# CTRL_MMR0_CFG0 register map
Vendor: Texas Instruments
Peripheral module from a debugger description file (folder J7VCL).
Registers are 32-bit, access per field, reset 0x0 unless marked. A register's access mark holds for its fields unless they carry their own. Offsets are as the file gives them; lines under a group give offsets from that group; [hi:lo] are bit positions; {n}, {i} and the like mark numbered series; 'fields as' and 'values as' point back to an identical list; <NAME> marks a mode.

## CTRL_MMR0_CFG0
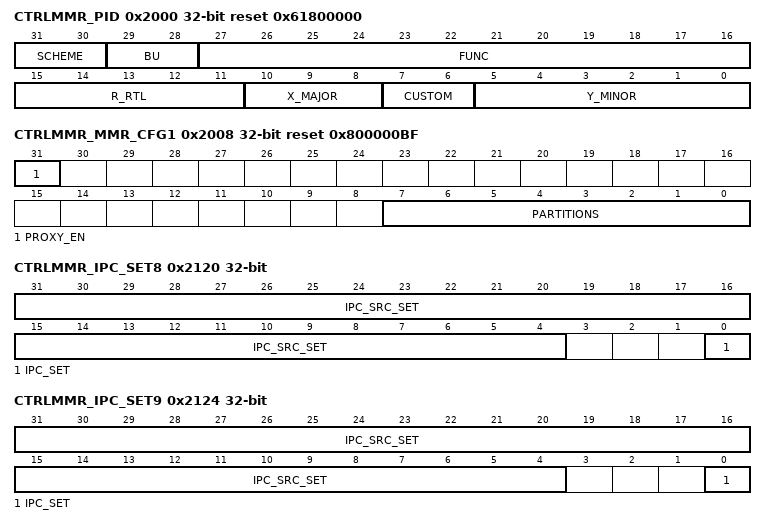
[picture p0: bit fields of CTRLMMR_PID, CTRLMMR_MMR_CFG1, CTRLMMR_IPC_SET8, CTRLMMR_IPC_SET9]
0x2000 CTRLMMR_PID ro reset 0x61800000
  [31:30] SCHEME
  [29:28] BU — Business unit - Processors
  [27:16] FUNC — Module functional identifier - CTRL MMR
  [15:11] R_RTL — RTL revision number
  [10:8] X_MAJOR — Major revision number
  [7:6] CUSTOM — Custom revision number
  [5:0] Y_MINOR — Minor revision number
0x2008 CTRLMMR_MMR_CFG1 ro reset 0x800000BF
  [31] PROXY_EN — Proxy addressing enabled
  [7:0] PARTITIONS — Indicates present partitions
0x2030 CTRLMMR_MAIN_DEVSTAT (reset mask 0xFFFFFF00)
  [7:0] BOOTMODE rw — Specifies the device Primary and Backup boot media.
0x2034 CTRLMMR_MAIN_BOOTCFG ro (reset mask 0xFFFFFF00)
  [7:0] BOOTMODE — Specifies the device Primary and Backup boot media as latched at PORz
0x2044 CTRLMMR_MAIN_FEATURE_STAT1 ro (reset mask 0xFFFEFFFF)
  [16] MCAN_FD_EN — FD mode is supported on MAIN MCAN interfaces when set
0x2120 CTRLMMR_IPC_SET8 access not given
  [31:4] IPC_SRC_SET — Read returns current value (access W1TS)
  [0] IPC_SET — Read returns 0 (access W1TS)
0x2124 CTRLMMR_IPC_SET9 access not given
  fields as CTRLMMR_IPC_SET8
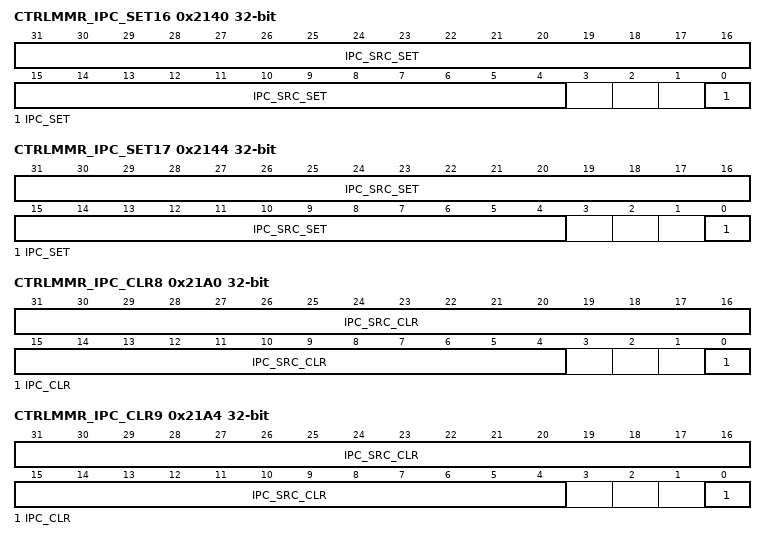
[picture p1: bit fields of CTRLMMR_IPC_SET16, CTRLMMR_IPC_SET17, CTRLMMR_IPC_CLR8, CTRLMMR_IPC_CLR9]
0x2140 CTRLMMR_IPC_SET16 access not given
  fields as CTRLMMR_IPC_SET8
0x2144 CTRLMMR_IPC_SET17 access not given
  fields as CTRLMMR_IPC_SET8
0x21A0 CTRLMMR_IPC_CLR8 access not given
  [31:4] IPC_SRC_CLR — Read returns current value (access W1TC)
  [0] IPC_CLR — Read returns current value (access W1TC)
0x21A4 CTRLMMR_IPC_CLR9 access not given
  fields as CTRLMMR_IPC_CLR8
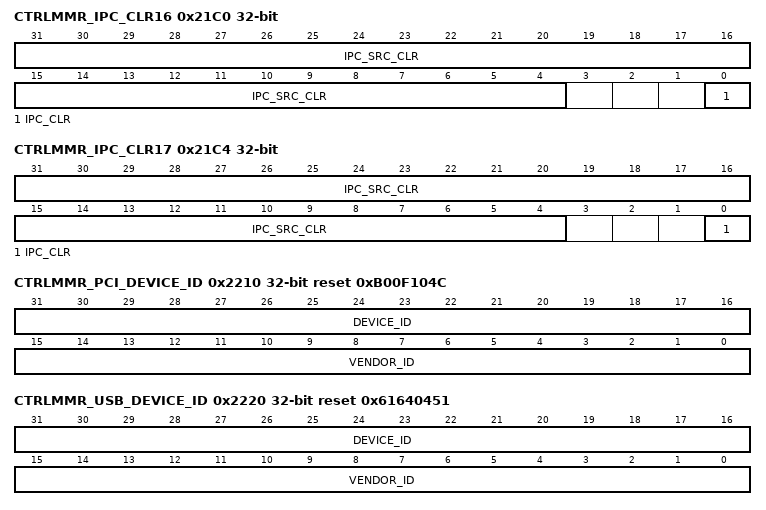
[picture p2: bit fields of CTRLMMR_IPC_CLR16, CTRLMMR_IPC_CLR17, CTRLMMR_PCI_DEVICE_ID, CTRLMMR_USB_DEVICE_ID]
0x21C0 CTRLMMR_IPC_CLR16 access not given
  fields as CTRLMMR_IPC_CLR8
0x21C4 CTRLMMR_IPC_CLR17 access not given
  fields as CTRLMMR_IPC_CLR8
0x2210 CTRLMMR_PCI_DEVICE_ID access not given reset 0xB00F104C
  [31:16] DEVICE_ID — Product ID (access WOT)
  [15:0] VENDOR_ID — TI Vendor ID (access WOT)
0x2220 CTRLMMR_USB_DEVICE_ID access not given reset 0x61640451
  fields as CTRLMMR_PCI_DEVICE_ID
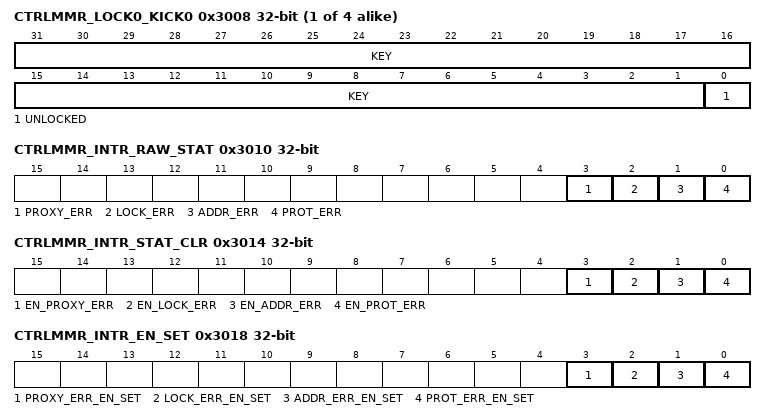
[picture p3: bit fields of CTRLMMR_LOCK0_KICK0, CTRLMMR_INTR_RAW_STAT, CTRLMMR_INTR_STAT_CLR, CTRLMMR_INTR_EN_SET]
{0x3008+0x4000*i} CTRLMMR_LOCK{i}_KICK0 (i=0..3)
  [31:1] KEY rw — Write the kick0 unlock value followed by the kick1 unlock value to unlock the write-protected Partition{i} registers
  [0] UNLOCKED ro — Unlock status. When set indicates that the proper unlock sequence has been performed and the partition is unlocked for writing.
{0x300C+0x4000*i} CTRLMMR_LOCK{i}_KICK1 rw (i=0..3)
  [31:0] KEY — Write the kick1 unlock value after the kick0 unlock value to unlock the write-protected Partition{i} registers
0x3010 CTRLMMR_INTR_RAW_STAT access not given
  [3] PROXY_ERR — Proxy violation occurred (attempt to write a Proxy1 claimed register through its Proxy0 address) (access W1TS)
  [2] LOCK_ERR — Lock violation occurred (attempt to write a write-locked register with partition locked) (access W1TS)
  [1] ADDR_ERR — Address violation occurred (attempt to read or write an invalid register address) (access W1TS)
  [0] PROT_ERR — Protection violation occurred (attempt to read or write a register with insufficient security or privilege access rights) (access W1TS)
0x3014 CTRLMMR_INTR_STAT_CLR access not given
  [3] EN_PROXY_ERR — Enabled proxy interrupt event status (access W1TC)
  [2] EN_LOCK_ERR — Enabled lock interrupt event status (access W1TC)
  [1] EN_ADDR_ERR — Enabled address interrupt event status (access W1TC)
  [0] EN_PROT_ERR — Enabled protection interrupt event status (access W1TC)
0x3018 CTRLMMR_INTR_EN_SET access not given
  [3] PROXY_ERR_EN_SET — Proxy interrupt enable (access W1TS)
  [2] LOCK_ERR_EN_SET — Lock interrupt enable (access W1TS)
  [1] ADDR_ERR_EN_SET — Address interrupt enable (access W1TS)
  [0] PROT_ERR_EN_SET — Protection interrupt enable (access W1TS)
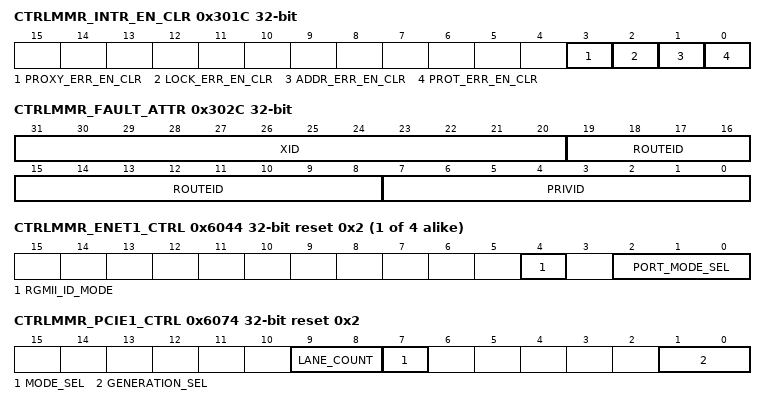
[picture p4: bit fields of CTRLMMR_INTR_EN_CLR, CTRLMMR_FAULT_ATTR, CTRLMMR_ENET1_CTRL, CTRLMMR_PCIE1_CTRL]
0x301C CTRLMMR_INTR_EN_CLR access not given
  [3] PROXY_ERR_EN_CLR — Proxy interrupt disable (access W1TC)
  [2] LOCK_ERR_EN_CLR — Lock interrupt disable (access W1TC)
  [1] ADDR_ERR_EN_CLR — Address interrupt disable (access W1TC)
  [0] PROT_ERR_EN_CLR — Protection interrupt disable (access W1TC)
0x3020 CTRLMMR_EOI
  [7:0] VECTOR rw
0x3024 CTRLMMR_FAULT_ADDR ro
  [31:0] ADDRESS — Address of the faulted access
0x3028 CTRLMMR_FAULT_TYPE ro
  [5:0] TYPE — Type of access which faulted 0h - No fault 1h - User execute access 2h - User write access 4h - User read access 8h - Supervisor execute access 10h - Supervisor write access 20h - Supervisor read access
0x302C CTRLMMR_FAULT_ATTR ro
  [31:20] XID — Transaction ID
  [19:8] ROUTEID
  [7:0] PRIVID — Privilege ID
0x3030 CTRLMMR_FAULT_CLR access not given
  [0] CLEAR — Fault clear (access W1TC)
{0x3100+4i} CTRLMMR_P0_CLAIM{i} rw (i=0..5)
  [31:0] PROXY1_CLAIMED — Proxy1 register claim bit
0x6000 CTRLMMR_USB0_CTRL
  [27] SERDES_SEL rw — Serdes Selection.
0x6008 CTRLMMR_USB0_PHY_CTRL reset 0x80000000
  [31] CORE_VOLTAGE rw — Selects the USB PHY core voltage
{0x6040+4i} CTRLMMR_ENET{i}_CTRL reset 0x2 (i=1..4)
  [4] RGMII_ID_MODE rw — Port{i} RGMII internal transmit delay selection
  [2:0] PORT_MODE_SEL rw — Selects Ethernet switch Port{i} interface 0h - GMII/MII (not supported) 1h - RMII 2h - RGMII 3h - SGMII 4h - QSGMII 5h - XFI (not supported) 6h - QSGMII_SUB 7h - Reserved
0x6074 CTRLMMR_PCIE1_CTRL reset 0x2
  [9:8] LANE_COUNT rw — Configures the PCIe lane count
  [7] MODE_SEL rw — Selects the operating mode
  [1:0] GENERATION_SEL rw — Configures the PCIe generation support in the PCIe capabilities linked-list 1h - Gen2 - Controller advertises Gen1 &amp; Gen2 capability and link operates at either speed 2h - Gen3 - Controller advertises Gen1, Gen2, &amp; Gen3 capability and link operates at any of the three speeds 3h - Reserved
0x6080 CTRLMMR_SERDES0_LN0_CTRL
  [1:0] LANE_FUNC_SEL rw — Selects the SERDES0 lane0 function 0h - IP1 - Enet Switch Q/SGMII Lane 3 1h - IP2 - PCIe1 Lane0 2h - IP3 - Not used 3h - IP4 - Not used
0x6084 CTRLMMR_SERDES0_LN1_CTRL
  [1:0] LANE_FUNC_SEL rw — Selects the SERDES0 lane1 function 0h - IP1 - Enet Switch Q/SGMII Lane 4 1h - IP2 - PCIe1 Lane1 2h - IP3 - USB3 3h - IP4 - Not Used
0x6088 CTRLMMR_SERDES0_LN2_CTRL
  [1:0] LANE_FUNC_SEL rw — Selects the SERDES0 lane2 function 0h - IP1 - Enet Switch Q/SGMII Lane 1 1h - IP2 - PCIe1 Lane2 2h - IP3 - Not Used 3h - IP4 - Not Used
0x608C CTRLMMR_SERDES0_LN3_CTRL
  [1:0] LANE_FUNC_SEL rw — Selects the SERDES0 lane3 function 0h - IP1 - Enet Switch Q/SGMII Lane 2 1h - IP2 - PCIe1 Lane3 2h - IP3 - USB3 3h - IP4 - Not Used
0x60E0 CTRLMMR_SERDES0_CTRL
  [8] RET_EN rw — Retention enable
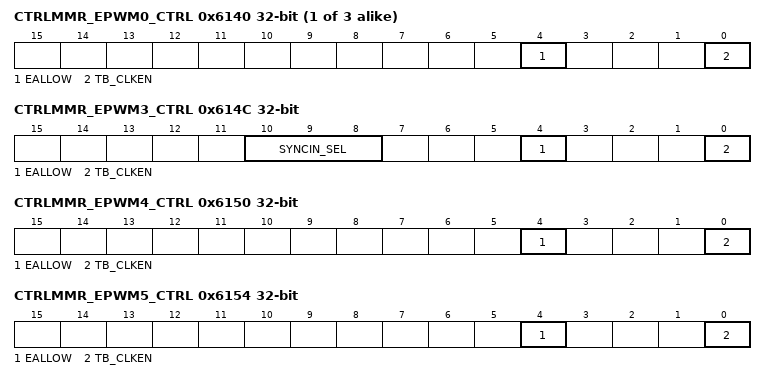
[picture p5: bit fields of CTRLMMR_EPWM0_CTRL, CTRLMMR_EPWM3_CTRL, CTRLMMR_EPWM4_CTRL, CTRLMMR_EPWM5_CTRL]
{0x6140+4i} CTRLMMR_EPWM{i}_CTRL (i=0..2)
  [4] EALLOW rw — Enable write access to ePWM tripzone and HRPWM config registers
  [0] TB_CLKEN rw — Enable eHRPWM timebase clock
0x614C CTRLMMR_EPWM3_CTRL
  [10:8] SYNCIN_SEL rw — Selects the source of the PWM3 synchronization input 0h - PWM3_SYNCIN Pin 1h - PWM2 syncout signal, daisy chained 2h - None 3h - None 4h - None 5h - None 6h - None 7h - None
  [4] EALLOW rw — Enable write access to ePWM tripzone and HRPWM config registers
  [0] TB_CLKEN rw — Enable eHRPWM timebase clock
0x6150 CTRLMMR_EPWM4_CTRL
  fields as CTRLMMR_EPWM0_CTRL
0x6154 CTRLMMR_EPWM5_CTRL
  fields as CTRLMMR_EPWM0_CTRL
0x6160 CTRLMMR_SOCA_SEL
  [1:0] SOCA_SEL rw — Selects the SOC A output source 0h - OR of all eHRPWM SOCA outputs 1h - None 2h - None 3h - None
0x6164 CTRLMMR_SOCB_SEL
  [1:0] SOCB_SEL rw — Selects the SOC B output source 0h - OR of all eHRPWM SOCB ouputs 1h - None 2h - None 3h - None
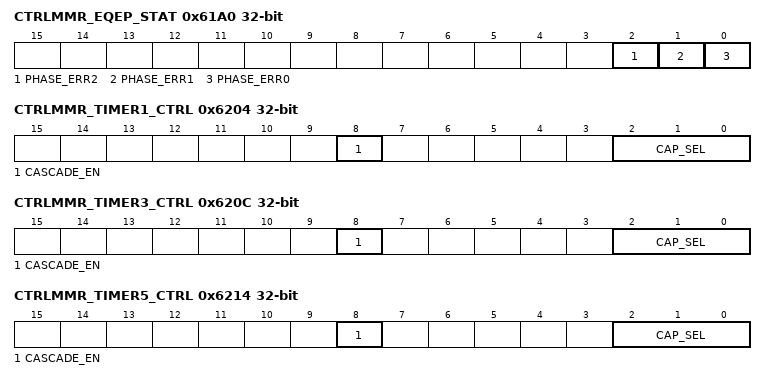
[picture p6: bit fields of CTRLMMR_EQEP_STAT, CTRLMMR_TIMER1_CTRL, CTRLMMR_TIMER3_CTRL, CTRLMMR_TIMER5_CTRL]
0x61A0 CTRLMMR_EQEP_STAT ro (reset mask 0xFFFFFFF8)
  [2] PHASE_ERR2 — eQEP2 Phase error status
  [1] PHASE_ERR1 — eQEP1 Phase error status
  [0] PHASE_ERR0 — eQEP0 Phase error status
0x61B4 CTRLMMR_SDIO1_CTRL (reset mask 0xFFFFFFE0)
  [4:0] DRV_STR rw — Selects the SDIO drive strength
0x6200 CTRLMMR_TIMER0_CTRL
  [2:0] CAP_SEL rw — Selects the TIMERIO input pin for capture input signal. This control is only used when TIMER0 is configured for capture operation. 0h - Use TIMERIO0 pin 1h - Use TIMERIO1 pin 2h - Use TIMERIO2 pin 3h - Use TIMERIO3 pin 4h - Use TIMERIO4 pin 5h - Use TIMERIO5 pin 6h - Use TIMERIO6 pin 7h - Use TIMERIO7 pin
0x6204 CTRLMMR_TIMER1_CTRL
  [8] CASCADE_EN rw — Enables cascading of TIMER1 to TIMER0
  [2:0] CAP_SEL rw — Selects the TIMERIO input pin for capture input signal. This control is only used when TIMER1 is configured for capture operation. 0h - Use TIMERIO0 pin 1h - Use TIMERIO1 pin 2h - Use TIMERIO2 pin 3h - Use TIMERIO3 pin 4h - Use TIMERIO4 pin 5h - Use TIMERIO5 pin 6h - Use TIMERIO6 pin 7h - Use TIMERIO7 pin
0x6208 CTRLMMR_TIMER2_CTRL
  [2:0] CAP_SEL rw — Selects the TIMERIO input pin for capture input signal. This control is only used when TIMER2 is configured for capture operation. 0h - Use TIMERIO0 pin 1h - Use TIMERIO1 pin 2h - Use TIMERIO2 pin 3h - Use TIMERIO3 pin 4h - Use TIMERIO4 pin 5h - Use TIMERIO5 pin 6h - Use TIMERIO6 pin 7h - Use TIMERIO7 pin
0x620C CTRLMMR_TIMER3_CTRL
  [8] CASCADE_EN rw — Enables cascading of TIMER3 to TIMER2
  [2:0] CAP_SEL rw — Selects the TIMERIO input pin for capture input signal. This control is only used when TIMER3 is configured for capture operation. 0h - Use TIMERIO0 pin 1h - Use TIMERIO1 pin 2h - Use TIMERIO2 pin 3h - Use TIMERIO3 pin 4h - Use TIMERIO4 pin 5h - Use TIMERIO5 pin 6h - Use TIMERIO6 pin 7h - Use TIMERIO7 pin
0x6210 CTRLMMR_TIMER4_CTRL
  [2:0] CAP_SEL rw — Selects the TIMERIO input pin for capture input signal. This control is only used when TIMER4 is configured for capture operation. 0h - Use TIMERIO0 pin 1h - Use TIMERIO1 pin 2h - Use TIMERIO2 pin 3h - Use TIMERIO3 pin 4h - Use TIMERIO4 pin 5h - Use TIMERIO5 pin 6h - Use TIMERIO6 pin 7h - Use TIMERIO7 pin
0x6214 CTRLMMR_TIMER5_CTRL
  [8] CASCADE_EN rw — Enables cascading of TIMER5 to TIMER4
  [2:0] CAP_SEL rw — Selects the TIMERIO input pin for capture input signal. This control is only used when TIMER5 is configured for capture operation. 0h - Use TIMERIO0 pin 1h - Use TIMERIO1 pin 2h - Use TIMERIO2 pin 3h - Use TIMERIO3 pin 4h - Use TIMERIO4 pin 5h - Use TIMERIO5 pin 6h - Use TIMERIO6 pin 7h - Use TIMERIO7 pin
0x6218 CTRLMMR_TIMER6_CTRL
  [2:0] CAP_SEL rw — Selects the TIMERIO input pin for capture input signal. This control is only used when TIMER6 is configured for capture operation. 0h - Use TIMERIO0 pin 1h - Use TIMERIO1 pin 2h - Use TIMERIO2 pin 3h - Use TIMERIO3 pin 4h - Use TIMERIO4 pin 5h - Use TIMERIO5 pin 6h - Use TIMERIO6 pin 7h - Use TIMERIO7 pin
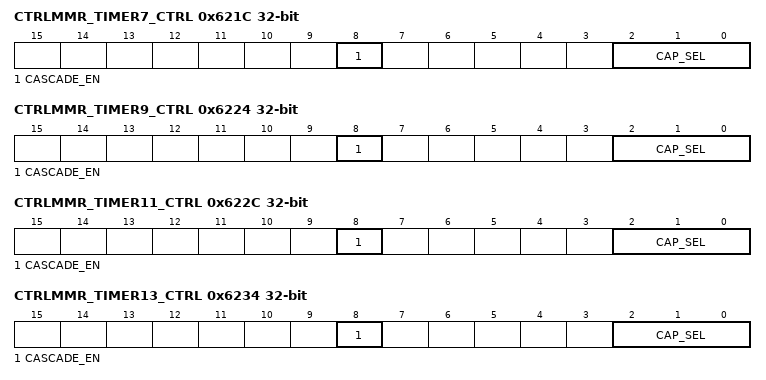
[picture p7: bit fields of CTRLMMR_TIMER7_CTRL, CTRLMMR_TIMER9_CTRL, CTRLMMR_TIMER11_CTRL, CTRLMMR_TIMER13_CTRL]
0x621C CTRLMMR_TIMER7_CTRL
  [8] CASCADE_EN rw — Enables cascading of TIMER7 to TIMER6
  [2:0] CAP_SEL rw — Selects the TIMERIO input pin for capture input signal. This control is only used when TIMER7 is configured for capture operation. 0h - Use TIMERIO0 pin 1h - Use TIMERIO1 pin 2h - Use TIMERIO2 pin 3h - Use TIMERIO3 pin 4h - Use TIMERIO4 pin 5h - Use TIMERIO5 pin 6h - Use TIMERIO6 pin 7h - Use TIMERIO7 pin
0x6220 CTRLMMR_TIMER8_CTRL
  [2:0] CAP_SEL rw — Selects the TIMERIO input pin for capture input signal. This control is only used when TIMER8 is configured for capture operation. 0h - Use TIMERIO0 pin 1h - Use TIMERIO1 pin 2h - Use TIMERIO2 pin 3h - Use TIMERIO3 pin 4h - Use TIMERIO4 pin 5h - Use TIMERIO5 pin 6h - Use TIMERIO6 pin 7h - Use TIMERIO7 pin
0x6224 CTRLMMR_TIMER9_CTRL
  [8] CASCADE_EN rw — Enables cascading of TIMER9 to TIMER8
  [2:0] CAP_SEL rw — Selects the TIMERIO input pin for capture input signal. This control is only used when TIMER9 is configured for capture operation. 0h - Use TIMERIO0 pin 1h - Use TIMERIO1 pin 2h - Use TIMERIO2 pin 3h - Use TIMERIO3 pin 4h - Use TIMERIO4 pin 5h - Use TIMERIO5 pin 6h - Use TIMERIO6 pin 7h - Use TIMERIO7 pin
0x6228 CTRLMMR_TIMER10_CTRL
  [2:0] CAP_SEL rw — Selects the TIMERIO input pin for capture input signal. This control is only used when TIMER10 is configured for capture operation. 0h - Use TIMERIO0 pin 1h - Use TIMERIO1 pin 2h - Use TIMERIO2 pin 3h - Use TIMERIO3 pin 4h - Use TIMERIO4 pin 5h - Use TIMERIO5 pin 6h - Use TIMERIO6 pin 7h - Use TIMERIO7 pin
0x622C CTRLMMR_TIMER11_CTRL
  [8] CASCADE_EN rw — Enables cascading of TIMER11 to TIMER10
  [2:0] CAP_SEL rw — Selects the TIMERIO input pin for capture input signal. This control is only used when TIMER11 is configured for capture operation. 0h - Use TIMERIO0 pin 1h - Use TIMERIO1 pin 2h - Use TIMERIO2 pin 3h - Use TIMERIO3 pin 4h - Use TIMERIO4 pin 5h - Use TIMERIO5 pin 6h - Use TIMERIO6 pin 7h - Use TIMERIO7 pin
0x6230 CTRLMMR_TIMER12_CTRL
  [2:0] CAP_SEL rw — Selects the TIMERIO input pin for capture input signal. This control is only used when TIMER12 is configured for capture operation. 0h - Use TIMERIO0 pin 1h - Use TIMERIO1 pin 2h - Use TIMERIO2 pin 3h - Use TIMERIO3 pin 4h - Use TIMERIO4 pin 5h - Use TIMERIO5 pin 6h - Use TIMERIO6 pin 7h - Use TIMERIO7 pin
0x6234 CTRLMMR_TIMER13_CTRL
  [8] CASCADE_EN rw — Enables cascading of TIMER13 to TIMER12
  [2:0] CAP_SEL rw — Selects the TIMERIO input pin for capture input signal. This control is only used when TIMER13 is configured for capture operation. 0h - Use TIMERIO0 pin 1h - Use TIMERIO1 pin 2h - Use TIMERIO2 pin 3h - Use TIMERIO3 pin 4h - Use TIMERIO4 pin 5h - Use TIMERIO5 pin 6h - Use TIMERIO6 pin 7h - Use TIMERIO7 pin
0x6238 CTRLMMR_TIMER14_CTRL
  [2:0] CAP_SEL rw — Selects the TIMERIO input pin for capture input signal. This control is only used when TIMER14 is configured for capture operation. 0h - Use TIMERIO0 pin 1h - Use TIMERIO1 pin 2h - Use TIMERIO2 pin 3h - Use TIMERIO3 pin 4h - Use TIMERIO4 pin 5h - Use TIMERIO5 pin 6h - Use TIMERIO6 pin 7h - Use TIMERIO7 pin
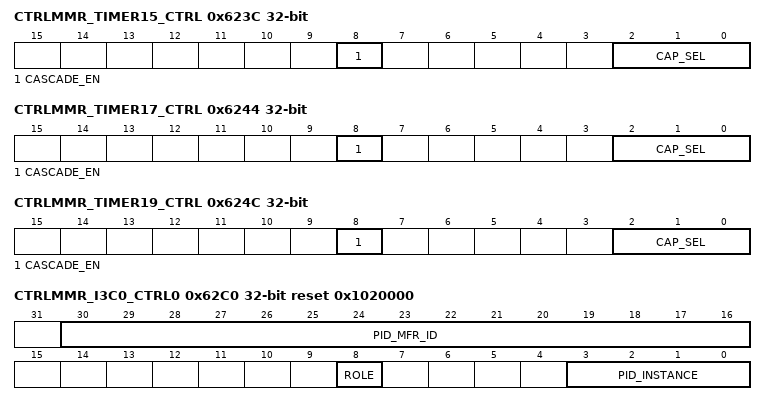
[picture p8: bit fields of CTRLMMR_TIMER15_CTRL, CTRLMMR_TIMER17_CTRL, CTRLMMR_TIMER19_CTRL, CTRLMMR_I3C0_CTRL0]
0x623C CTRLMMR_TIMER15_CTRL
  [8] CASCADE_EN rw — Enables cascading of TIMER15 to TIMER14
  [2:0] CAP_SEL rw — Selects the TIMERIO input pin for capture input signal. This control is only used when TIMER15 is configured for capture operation. 0h - Use TIMERIO0 pin 1h - Use TIMERIO1 pin 2h - Use TIMERIO2 pin 3h - Use TIMERIO3 pin 4h - Use TIMERIO4 pin 5h - Use TIMERIO5 pin 6h - Use TIMERIO6 pin 7h - Use TIMERIO7 pin
0x6240 CTRLMMR_TIMER16_CTRL
  [2:0] CAP_SEL rw — Selects the TIMERIO input pin for capture input signal. This control is only used when TIMER16 is configured for capture operation. 0h - Use TIMERIO0 pin 1h - Use TIMERIO1 pin 2h - Use TIMERIO2 pin 3h - Use TIMERIO3 pin 4h - Use TIMERIO4 pin 5h - Use TIMERIO5 pin 6h - Use TIMERIO6 pin 7h - Use TIMERIO7 pin
0x6244 CTRLMMR_TIMER17_CTRL
  [8] CASCADE_EN rw — Enables cascading of TIMER17 to TIMER16
  [2:0] CAP_SEL rw — Selects the TIMERIO input pin for capture input signal. This control is only used when TIMER17 is configured for capture operation. 0h - Use TIMERIO0 pin 1h - Use TIMERIO1 pin 2h - Use TIMERIO2 pin 3h - Use TIMERIO3 pin 4h - Use TIMERIO4 pin 5h - Use TIMERIO5 pin 6h - Use TIMERIO6 pin 7h - Use TIMERIO7 pin
0x6248 CTRLMMR_TIMER18_CTRL
  [2:0] CAP_SEL rw — Selects the TIMERIO input pin for capture input signal. This control is only used when TIMER18 is configured for capture operation. 0h - Use TIMERIO0 pin 1h - Use TIMERIO1 pin 2h - Use TIMERIO2 pin 3h - Use TIMERIO3 pin 4h - Use TIMERIO4 pin 5h - Use TIMERIO5 pin 6h - Use TIMERIO6 pin 7h - Use TIMERIO7 pin
0x624C CTRLMMR_TIMER19_CTRL
  [8] CASCADE_EN rw — Enables cascading of TIMER19 to TIMER18
  [2:0] CAP_SEL rw — Selects the TIMERIO input pin for capture input signal. This control is only used when TIMER19 is configured for capture operation. 0h - Use TIMERIO0 pin 1h - Use TIMERIO1 pin 2h - Use TIMERIO2 pin 3h - Use TIMERIO3 pin 4h - Use TIMERIO4 pin 5h - Use TIMERIO5 pin 6h - Use TIMERIO6 pin 7h - Use TIMERIO7 pin
{0x6280+4i} CTRLMMR_TIMERIO{i}_CTRL (i=0..7)
  [4:0] OUT_SEL rw — Selects the source of the TIMERIO{i} output 0h - TIMERIO{i} is driven by TIMER0 output 1h - TIMERIO{i} is driven by TIMER1 output 2h - TIMERIO{i} is driven by TIMER2 output 3h - TIMERIO{i} is driven by TIMER3 output 4h - TIMERIO{i} is driven by TIMER4 output 5h - TIMERIO{i} is driven by TIMER5 output 6h - TIMERIO{i} is driven by TIMER6 output 7h - TIMERIO{i} is driven by TIMER7 output 8h - TIMERIO{i} is driven by TIMER8 output 9h - TIMERIO{i} is driven by TIMER9 output Ah - TIMERIO{i} is driven by TIMER10 output Bh - TIMERIO{i} is driven by TIMER11 output Ch - TIMERIO{i} is driven by TIMER12 output Dh - TIMERIO{i} is driven by TIMER13 output Eh - TIMERIO{i} is driven by TIMER14 output Fh - TIMERIO{i} is driven by TIMER15 output 10h - TIMERIO{i} is driven by TIMER16 output 11h - TIMERIO{i} is driven by TIMER17 output 12h - TIMERIO{i} is driven by TIMER18 output 13h - TIMERIO{i} is driven by TIMER19 output
0x62C0 CTRLMMR_I3C0_CTRL0 reset 0x1020000
  [30:16] PID_MFR_ID rw — Manufacturer ID
  [8] ROLE rw — Master Role
  [3:0] PID_INSTANCE rw — Provisional ID Instance. This input corresponds to bits[15:12] of the Provisional ID. It is intended to provide a way of differentiating several I3C devices if there would be no other way to have each manufactured device have a unique Provisional ID
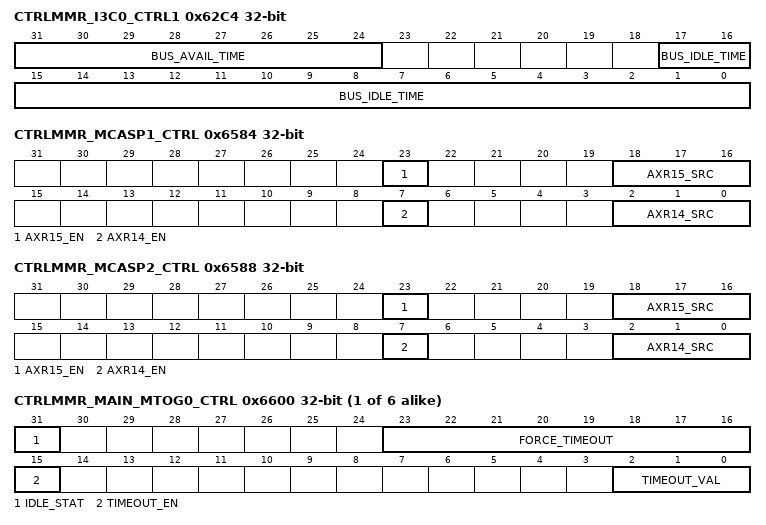
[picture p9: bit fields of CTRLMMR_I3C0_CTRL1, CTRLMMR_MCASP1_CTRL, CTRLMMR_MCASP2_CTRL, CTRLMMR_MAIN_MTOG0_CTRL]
0x62C4 CTRLMMR_I3C0_CTRL1
  [31:24] BUS_AVAIL_TIME rw — Indicates the number of sclk cycles in the Bus Available condition
  [17:0] BUS_IDLE_TIME rw — Indicates the number of sclk cycles in the Bus Idle condition
0x62E0 CTRLMMR_I2C0_CTRL
  [0] HS_MCS_EN rw — HS Mode master current source enable.
0x6584 CTRLMMR_MCASP1_CTRL
  [23] AXR15_EN rw — Enable AXR15 receive data.
  [18:16] AXR15_SRC rw — Selects one of the AFSX or AFSR inputs as the AXR15 data input 0h - McASP0_AFSR 1h - McASP0_AFSX 2h - McASP1_AFSR 3h - McASP1_AFSX 4h - McASP2_AFSR 5h - McASP2_AFSX 6h - '0' 7h - '0'
  [7] AXR14_EN rw — Enable AXR14 receive data.
  [2:0] AXR14_SRC rw — Selects one of the AFSX or AFSR inputs as the AXR14 data input 0h - McASP0_AFSR 1h - McASP0_AFSX 2h - McASP1_AFSR 3h - McASP1_AFSX 4h - McASP2_AFSR 5h - McASP2_AFSX 6h - '0' 7h - '0'
0x6588 CTRLMMR_MCASP2_CTRL
  fields as CTRLMMR_MCASP1_CTRL
{0x6600+4i} CTRLMMR_MAIN_MTOG{i}_CTRL (reset mask 0x7FFFFFFF) (i=0..5)
  [31] IDLE_STAT ro — Idle status
  [23:16] FORCE_TIMEOUT rw — Force Timout
  [15] TIMEOUT_EN rw — Timeout Enable
  [2:0] TIMEOUT_VAL rw — Gasket Timeout Value 0h - 1024 clock cycles 1h - 4096 clock cycles 2h - 16,384 clock cycles 3h - 65,536 clock cycles 4h - 262,144 clock cycles 5h - 1,048,576 clock cycles 6h - 2,097,152 clock cycles 7h - 4,194,303 clock cycles
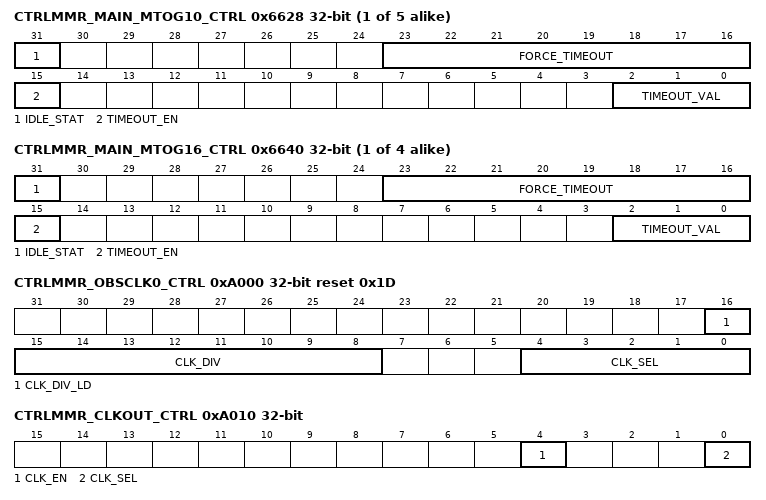
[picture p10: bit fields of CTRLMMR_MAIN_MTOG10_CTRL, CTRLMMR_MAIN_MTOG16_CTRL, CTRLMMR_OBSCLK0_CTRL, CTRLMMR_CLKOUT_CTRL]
{0x6600+4i} CTRLMMR_MAIN_MTOG{i}_CTRL (reset mask 0x7FFFFFFF) (i=10..14)
  fields as CTRLMMR_MAIN_MTOG0_CTRL
{0x6600+4i} CTRLMMR_MAIN_MTOG{i}_CTRL (reset mask 0x7FFFFFFF) (i=16..19)
  fields as CTRLMMR_MAIN_MTOG0_CTRL
0x66C0 CTRLMMR_CC_EN_FLUSH_CTRL
  [15:0] FLUSH rw — Flush ARM / MSMC Interface Transactions
{0x7100+4i} CTRLMMR_P1_CLAIM{i} rw (i=0..7)
  [31:0] PROXY1_CLAIMED — Proxy1 register claim bit
{0x7100+4i} CTRLMMR_P1_CLAIM{i} rw (i=10..15)
  [31:0] PROXY1_CLAIMED — Proxy1 register claim bit
0xA000 CTRLMMR_OBSCLK0_CTRL reset 0x1D
  [16] CLK_DIV_LD rw — Load the output divider value
  [15:8] CLK_DIV rw — OBSCLK0 output divider
  [4:0] CLK_SEL rw — OBSCLK0 clock source selection. 0h - MAIN_PLL0_HSDIV0_CLKOUT 1h - MAIN_PLL1_HSDIV0_CLKOUT 2h - MAIN_PLL2_HSDIV1_CLKOUT 3h - MAIN_PLL3_HSDIV0_CLKOUT 4h - MAIN_PLL4_HSDIV0_CLKOUT 5h - '0' 6h - '0' 7h - '0' 8h - '0' 9h - '0' Ah - '0' Bh - '0' Ch - MAIN_PLL12_HSDIV0_CLKOUT Dh - OBSCLK1 OUT Eh - MAIN_PLL14_HSDIV0_CLKOUT Fh - '0' 10h - '0' 11h - '0' 12h - '0' 13h - '0' 14h - '0' 15h - '0' 16h - '0' 17h - '0' 18h - '0' 19h - '0' 1Ah - CPTS_GENF3 1Bh - CLK_12M_RC 1Ch - LFXOSC_CLKOUT 1Dh - PLLCTRL_OBSCLK 1Eh - HFOSC1_CLKOUT 1Fh - HFOSC0_CLKOUT
0xA004 CTRLMMR_OBSCLK1_CTRL
  [1:0] CLK_SEL rw — OBSCLK1_OUT signal output clock source selection 0h - '0' 1h - MAIN_PLL8_HSDIV0_CLKOUT / DIV8 2h - '0' 3h - '0'
0xA010 CTRLMMR_CLKOUT_CTRL
  [4] CLK_EN rw — When set, enables CLKOUT output
  [0] CLK_SEL rw — Selects CLKOUT clock source
0xA030 CTRLMMR_GTC_CLKSEL
  [3:0] CLK_SEL rw — Selects the GTC timebase clock source 0h - MAIN_PLL3_HSDIV1_CLKOUT 1h - MAIN_PLL0_HSDIV6_CLKOUT 2h - MCU_CPTS_REF_CLK (pin) 3h - CPTS_RFT_CLK (pin) 4h - MCU_EXT_REFCLK0 (pin) 5h - EXT_REFCLK1 (pin) 6h - SERDES0_IP2_LN0_TXMCLK 7h - SERDES0_IP2_LN1_TXMCLK 8h - SERDES0_IP2_LN2_TXMCLK 9h - SERDES0_IP2_LN3_TXMCLK Ah - '0' Bh - '0' Ch - '0' Dh - '0' Eh - MCU_PLL2_HSDIV1_CLKOUT Fh - MAIN_SYSCLK0
0xA03C CTRLMMR_EFUSE_CLKSEL
  [0] CLK_SEL rw — Selects the clock source 0h - HFOSC0_CLKOUT 1h - MAIN_SYSCLK0 / 4
0xA084 CTRLMMR_PCIE1_CLKSEL
  [3:0] CPTS_CLKSEL rw — Selects the clock source for the PCIE1 Common Platform Time Stamp module 0h - MAIN_PLL3_HSDIV1_CLKOUT 1h - MAIN_PLL0_HSDIV6_CLKOUT 2h - MCU_CPTS_REF_CLK (pin) 3h - CPTS_RFT_CLK (pin) 4h - MCU_EXT_REFCLK0 (pin) 5h - EXT_REFCLK1 (pin) 6h - SERDES0_IP2_LN0_TXMCLK 7h - SERDES0_IP2_LN1_TXMCLK 8h - SERDES0_IP2_LN2_TXMCLK 9h - SERDES0_IP2_LN3_TXMCLK Ah - '0' Bh - '0' Ch - '0' Dh - '0' Eh - MCU_PLL2_HSDIV1_CLKOUT Fh - MAIN_SYSCLK0
0xA090 CTRLMMR_CPSW_CLKSEL
  [3:0] CPTS_CLKSEL rw — Selects the clock source for the CPSW Ethernet switch Common Platform Time Stamp module 0h - MAIN_PLL3_HSDIV1_CLKOUT 1h - MAIN_PLL0_HSDIV6_CLKOUT 2h - MCU_CPTS_REF_CLK (pin) 3h - CPTS_RFT_CLK (pin) 4h - MCU_EXT_REFCLK0 (pin) 5h - EXT_REFCLK1 (pin) 6h - SERDES0_IP2_LN0_TXMCLK 7h - SERDES0_IP2_LN1_TXMCLK 8h - SERDES0_IP2_LN2_TXMCLK 9h - SERDES0_IP2_LN3_TXMCLK Ah - '0' Bh - '0' Ch - '0' Dh - '0' Eh - MCU_PLL2_HSDIV1_CLKOUT Fh - MAIN_SYSCLK0
0xA098 CTRLMMR_NAVSS_CLKSEL
  [3:0] CPTS_CLKSEL rw — Selects the clock source for the SoC] Common Platform Time Stamp module located within the Nav Subsystem 0h - MAIN_PLL3_HSDIV1_CLKOUT 1h - MAIN_PLL0_HSDIV6_CLKOUT 2h - MCU_CPTS_REF_CLK (pin) 3h - CPTS_RFT_CLK (pin) 4h - MCU_EXT_REFCLK0 (pin) 5h - EXT_REFCLK1 (pin) 6h - SERDES0_IP2_LN0_TXMCLK 7h - SERDES0_IP2_LN1_TXMCLK 8h - SERDES0_IP2_LN2_TXMCLK 9h - SERDES0_IP2_LN3_TXMCLK Ah - '0' Bh - '0' Ch - '0' Dh - '0' Eh - MCU_PLL2_HSDIV1_CLKOUT Fh - MAIN_SYSCLK0
0xA0B0 CTRLMMR_EMMC0_CLKSEL
  [1:0] CLK_SEL rw — eMMC XIN_CLK selection
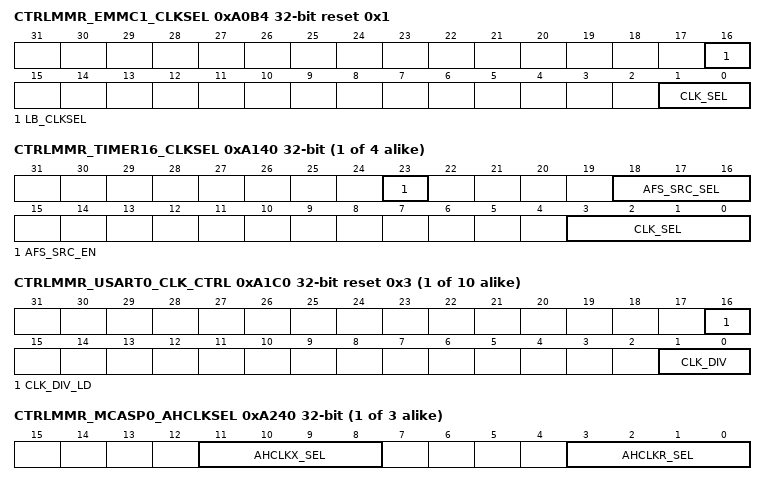
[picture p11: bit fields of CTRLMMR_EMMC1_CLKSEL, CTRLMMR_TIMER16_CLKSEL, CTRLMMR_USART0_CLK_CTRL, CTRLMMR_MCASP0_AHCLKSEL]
0xA0B4 CTRLMMR_EMMC1_CLKSEL reset 0x1
  [16] LB_CLKSEL rw — eMMC Loopback clock selection
  [1:0] CLK_SEL rw — eMMC XIN_CLK selection
0xA0D0 CTRLMMR_GPMC_CLKSEL
  [1:0] CLK_SEL rw — Selects the GPMC clock source
0xA0E0 CTRLMMR_USB0_CLKSEL
  [0] REFCLK_SEL rw — Selects the clock source for the USB0 ref_clk.
{0xA100+4i} CTRLMMR_TIMER{i}_CLKSEL (i=0..15)
  [3:0] CLK_SEL rw — Timer functional clock input select mux control 0h - HFOSC0_CLKOUT 1h - HFOSC1_CLKOUT 2h - MAIN_PLL0_HSDIV1_CLKOUT 3h - CLK_12M_RC 4h - MAIN_PLL3_HSDIV3_CLKOUT 5h - MCU_EXT_REFCLK0 (pin) 6h - EXT_REFCLK1 (pin) 7h - LFXOSC_CLKOUT 8h - CPTS_RFT_CLK (pin) 9h - MAIN_PLL1_HSDIV3_CLKOUT Ah - MAIN_PLL2_HSDIV6_CLKOUT Bh - MAIN_PLL4_HSDIV2_CLKOUT Ch - CPTS_GENF2 Dh - CPTS_GENF3 Eh - CPSW5X_CPTS_GENF0 Fh - CPTS_GENF4
{0xA100+4i} CTRLMMR_TIMER{i}_CLKSEL (i=16..19)
  [23] AFS_SRC_EN rw — Enable AFS source mux output as the Timer clock source. Note that for TIMER17 and TIMER19 this selection will be overridden if cascade_en in the associated TIMERn_CTRL register is set.
  [18:16] AFS_SRC_SEL rw — Selects the ASFR/AFSX input to use as a timer clock when afs_src_en is set. 0h - McASP0_AFSR 1h - McASP0_AFSX 2h - McASP1_AFSR 3h - McASP1_AFSX 4h - McASP2_AFSR 5h - McASP2_AFSX 6h - '0' 7h - '0'
  [3:0] CLK_SEL rw — Timer functional clock input select mux control 0h - HFOSC0_CLKOUT 1h - HFOSC1_CLKOUT 2h - MAIN_PLL0_HSDIV1_CLKOUT 3h - CLK_12M_RC 4h - MAIN_PLL3_HSDIV3_CLKOUT 5h - MCU_EXT_REFCLK0 (pin) 6h - EXT_REFCLK1 (pin) 7h - LFXOSC_CLKOUT 8h - CPTS_RFT_CLK (pin) 9h - MAIN_PLL1_HSDIV3_CLKOUT Ah - MAIN_PLL2_HSDIV6_CLKOUT Bh - MAIN_PLL4_HSDIV2_CLKOUT Ch - CPTS_GENF2 Dh - CPTS_GENF3 Eh - CPSW5X_CPTS_GENF0 Fh - CPTS_GENF4
{0xA190+4i} CTRLMMR_SPI{i}_CLKSEL (i=0..3)
  [16] MSTR_LB_CLKSEL rw — Master mode receive capture clock loopback selection
{0xA190+4i} CTRLMMR_SPI{i}_CLKSEL (i=5..7)
  fields as CTRLMMR_SPI0_CLKSEL
{0xA1C0+4i} CTRLMMR_USART{i}_CLK_CTRL reset 0x3 (i=0..9)
  [16] CLK_DIV_LD rw — Load the output divider value
  [1:0] CLK_DIV rw — Selects the clock divider value. Supports divide values of 1 to 4 Default is /4. To load the new divider value the clk_div_ld bit must be cleared and then set to 1. 0h - Divide by 1 1h - Divide by 2 2h - Divide by 3 3h - Divide by 4
{0xA200+4i} CTRLMMR_MCASP{i}_CLKSEL (i=0..2)
  [2:0] AUXCLK_SEL rw — Selects the McASP{i} auxclk clock source 0h - MAIN_PLL4_HSDIV0_CLKOUT 1h - MAIN_PLL2_HSDIV2_CLKOUT 2h - '0' 3h - '0' 4h - ATCLK0 5h - ATCLK1 6h - ATCLK2 7h - ATCLK3
{0xA240+4i} CTRLMMR_MCASP{i}_AHCLKSEL (i=0..2)
  [11:8] AHCLKX_SEL rw — Selects the AHCLKX input source for McASP{i} 0h - HFOSC1_CLKOUT 1h - HFOSC0_CLKOUT 2h - AUDIO_EXT_REFCLK0_IN 3h - AUDIO_EXT_REFCLK1_IN 4h - '0' 5h - '0' 6h - '0' 7h - '0' 8h - ATCLK0 9h - ATCLK1 Ah - ATCLK2 Bh - ATCLK3
  [3:0] AHCLKR_SEL rw — Selects the AHCLKR input source for McASP{i} 0h - HFOSC1_CLKOUT 1h - HFOSC0_CLKOUT 2h - AUDIO_EXT_REFCLK0_IN 3h - AUDIO_EXT_REFCLK1_IN 4h - '0' 5h - '0' 6h - '0' 7h - '0' 8h - ATCLK0 9h - ATCLK1 Ah - ATCLK2 Bh - ATCLK3 Ch - '0' Dh - '0' Eh - '0' Fh - '0'
{0xA2A0+4i} CTRLMMR_ATL_BWS{i}_SEL (i=0..3)
  [4:0] WD_SEL rw — BWS source signal 0h - McASP0 AFSR Pin Input 1h - McASP1 AFSR Pin Input 2h - McASP2 AFSR Pin Input 3h - '0' 4h - '0' 5h - '0' 6h - '0' 7h - '0' 8h - '0' 9h - '0' Ah - '0' Bh - '0' Ch - McASP0 AFSX Pin Input Dh - McASP1 AFSX Pin Input Eh - McASP2 AFSX Pin Input Fh - '0' 10h - '0' 11h - '0' 12h - '0' 13h - '0' 14h - '0' 15h - '0' 16h - '0' 17h - '0' 18h - AUDIO_EXT_REFCLK0 Pin input 19h - AUDIO_EXT_REFCLK1 Pin input 1Ah - '0' 1Bh - '0'
{0xA2B0+4i} CTRLMMR_ATL_AWS{i}_SEL (i=0..3)
  [4:0] WD_SEL rw — AWS source signal 0h - McASP0 AFSX Pin Input 1h - McASP1 AFSX Pin Input 2h - McASP2 AFSX Pin Input 3h - '0' 4h - '0' 5h - '0' 6h - '0' 7h - '0' 8h - '0' 9h - '0' Ah - '0' Bh - '0' Ch - McASP0 AFSX Pin Input Dh - McASP1 AFSX Pin Input Eh - McASP2 AFSX Pin Input Fh - '0' 10h - '0' 11h - '0' 12h - '0' 13h - '0' 14h - '0' 15h - '0' 16h - '0' 17h - '0' 18h - AUDIO_EXT_REFCLK0 Pin input 19h - AUDIO_EXT_REFCLK1 Pin input 1Ah - '0' 1Bh - '0' 1Ch - '0' 1Dh - '0'
0xA2C0 CTRLMMR_ATL_CLKSEL
  [3:0] PCLK_SEL rw — Selects the PCLK clock source 0h - MAIN_PLL4_HSDIV1_CLKOUT 1h - MAIN_PLL2_HSDIV2_CLKOUT 2h - '0' 3h - '0' 4h - MAIN_PLL0_HSDIV7_CLKOUT 5h - MCU_EXT_REFCLK0 (pin) 6h - EXT_REFCLK1 (pin) 7h - '0'
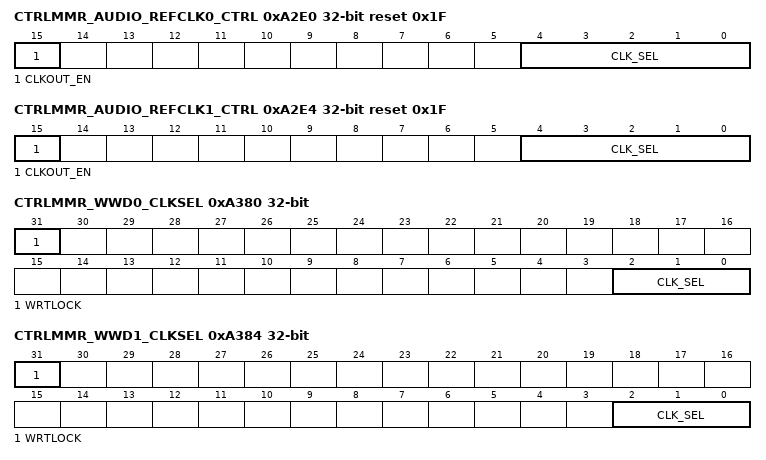
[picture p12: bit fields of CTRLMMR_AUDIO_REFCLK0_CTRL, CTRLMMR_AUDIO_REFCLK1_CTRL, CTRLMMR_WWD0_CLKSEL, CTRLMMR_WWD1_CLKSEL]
0xA2E0 CTRLMMR_AUDIO_REFCLK0_CTRL reset 0x1F
  [15] CLKOUT_EN rw — AUDIO_REFCLK 0 output enable
  [4:0] CLK_SEL rw — Clock source 0h - MCASP0 AHCLKR Output 1h - MCASP1 AHCLKR Output 2h - MCASP2 AHCLKR Output 3h - Reserved 4h - Reserved 5h - Reserved 6h - Reserved 7h - Reserved 8h - Reserved 9h - Reserved Ah - Reserved Bh - Reserved Ch - MCASP0 AHCLKX Output Dh - MCASP1 AHCLKX Output Eh - MCASP2 AHCLKX Output Fh - Reserved 10h - Reserved 11h - Reserved 12h - Reserved 13h - Reserved 14h - Reserved 15h - Reserved 16h - Reserved 17h - Reserved 18h - ATCLK0 19h - ATCLK1 1Ah - ATCLK2 1Bh - ATCLK3 1Ch - MAIN_PLL4_HSDIV2_CLKOUT 1Dh - '0' 1Eh - '0' 1Fh - '0'
0xA2E4 CTRLMMR_AUDIO_REFCLK1_CTRL reset 0x1F
  [15] CLKOUT_EN rw — AUDIO_REFCLK 1 output enable
  [4:0] CLK_SEL rw — Clock source 0h - MCASP0 AHCLKR Output 1h - MCASP1 AHCLKR Output 2h - MCASP2 AHCLKR Output 3h - Reserved 4h - Reserved 5h - Reserved 6h - Reserved 7h - Reserved 8h - Reserved 9h - Reserved Ah - Reserved Bh - Reserved Ch - MCASP0 AHCLKX Output Dh - MCASP1 AHCLKX Output Eh - MCASP2 AHCLKX Output Fh - Reserved 10h - Reserved 11h - Reserved 12h - Reserved 13h - Reserved 14h - Reserved 15h - Reserved 16h - Reserved 17h - Reserved 18h - ATCLK0 19h - ATCLK1 1Ah - ATCLK2 1Bh - ATCLK3 1Ch - MAIN_PLL4_HSDIV2_CLKOUT 1Dh - '0' 1Eh - '0' 1Fh - '0'
0xA380 CTRLMMR_WWD0_CLKSEL
  [31] WRTLOCK rw — When set, locks
  [2:0] CLK_SEL rw — Windowed watchdog timer functional clock input select mux control 0h - HFOSC0_CLKOUT 1h - LFXOSC_CLKOUT 2h - CLK_12M_RC 3h - CLK_32K 4h - HFOSC1_CLKOUT 5h - reserved (HFOSC1_CLKOUT) 6h - reserved (HFOSC1_CLKOUT) 7h - reserved (HFOSC1_CLKOUT)
0xA384 CTRLMMR_WWD1_CLKSEL
  fields as CTRLMMR_WWD0_CLKSEL
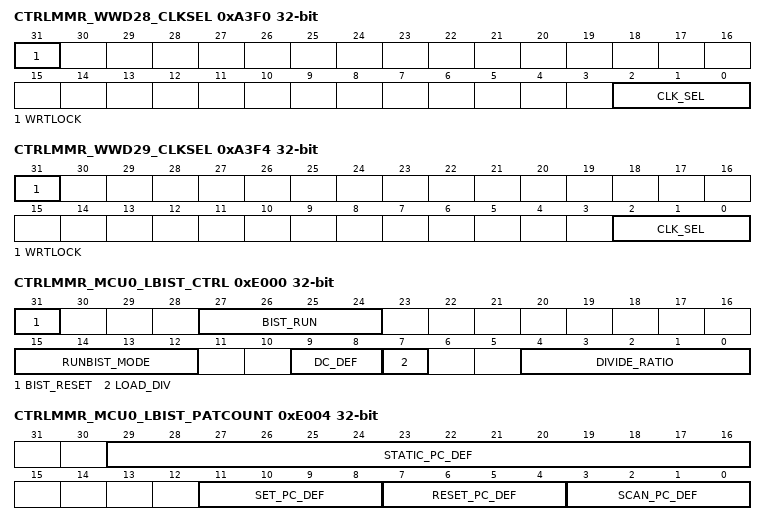
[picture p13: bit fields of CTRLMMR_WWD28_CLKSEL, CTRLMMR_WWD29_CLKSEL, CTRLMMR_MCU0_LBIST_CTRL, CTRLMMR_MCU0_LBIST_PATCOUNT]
0xA3F0 CTRLMMR_WWD28_CLKSEL
  fields as CTRLMMR_WWD0_CLKSEL
0xA3F4 CTRLMMR_WWD29_CLKSEL
  fields as CTRLMMR_WWD0_CLKSEL
0xA400 CTRLMMR_SERDES0_CLKSEL
  [1:0] CORE_REFCLK_SEL rw — Selects the source for the core_refclk input 0h - HFOSC0_CLKOUT 1h - HFOSC1_CLKOUT 2h - MAIN_PLL3_HSDIV4_CLKOUT 3h - MAIN_PLL2_HSDIV4_CLKOUT
{0xA480+4i} CTRLMMR_MCAN{i}_CLKSEL (i=0..17)
  [1:0] CLK_SEL rw — MAIN MCAN_CLK selection
{0xB100+4i} CTRLMMR_P2_CLAIM{i} rw (i=0..9)
  [31:0] PROXY1_CLAIMED — Proxy1 register claim bit
0xE000 CTRLMMR_MCU0_LBIST_CTRL
  [31] BIST_RESET rw — Reset LBIST macro
  [27:24] BIST_RUN rw — Starts LBIST if all bits are 1
  [15:12] RUNBIST_MODE rw — Runbist mode enable if all bits are 1
  [9:8] DC_DEF rw — Clock delay after scan_enable switching
  [7] LOAD_DIV rw — Loads LBIST clock divide ratio on transition from 0 to 1
  [4:0] DIVIDE_RATIO rw — LBIST clock divide ratio
0xE004 CTRLMMR_MCU0_LBIST_PATCOUNT
  [29:16] STATIC_PC_DEF rw — Number of stuck-at patterns to run
  [11:8] SET_PC_DEF rw — Number of set patterns to run
  [7:4] RESET_PC_DEF rw — Number of reset patterns to run
  [3:0] SCAN_PC_DEF rw — Number of chain test patterns to run
0xE008 CTRLMMR_MCU0_LBIST_SEED0 rw
  [31:0] PRPG_DEF — Initial seed for PRPG (bits 31:0)
0xE00C CTRLMMR_MCU0_LBIST_SEED1
  [20:0] PRPG_DEF rw — Initial seed for PRPG (bits 52:32)
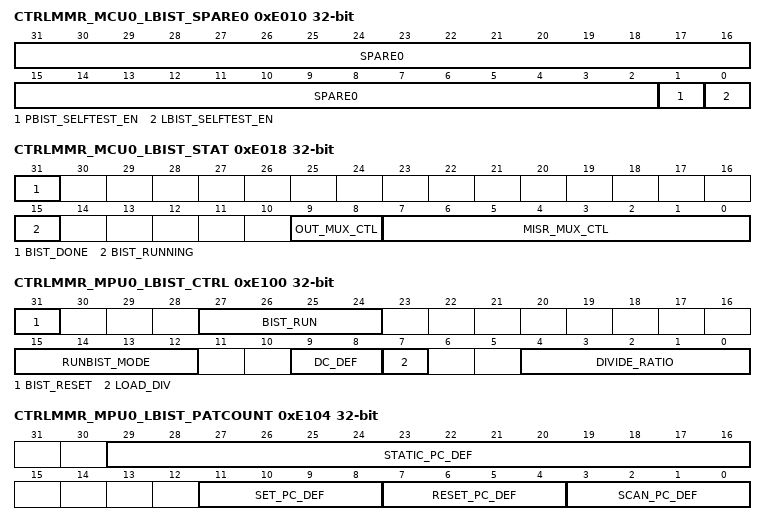
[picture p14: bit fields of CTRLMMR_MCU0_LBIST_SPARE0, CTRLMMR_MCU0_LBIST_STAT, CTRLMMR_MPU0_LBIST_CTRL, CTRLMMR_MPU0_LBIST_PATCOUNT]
0xE010 CTRLMMR_MCU0_LBIST_SPARE0 rw
  [31:2] SPARE0 — LBIST spare bits
  [1] PBIST_SELFTEST_EN — PBIST isolation control
  [0] LBIST_SELFTEST_EN — LBIST isolation control
0xE014 CTRLMMR_MCU0_LBIST_SPARE1 rw
  [31:0] SPARE1 — LBIST spare bits
0xE018 CTRLMMR_MCU0_LBIST_STAT (reset mask 0x7FFF7FFF)
  [31] BIST_DONE ro — LBIST is done
  [15] BIST_RUNNING ro — LBIST is running
  [9:8] OUT_MUX_CTL rw — Selects source of LBIST output
  [7:0] MISR_MUX_CTL rw — Selects block of 32 MISR bits to read. A value of 0 selects a compacted 32-bit version of the full MISR. A value of 1-32 select a 32-bit segment of the MISR.
0xE01C CTRLMMR_MCU0_LBIST_MISR ro reset not defined
  [31:0] MISR_RESULT — 32-bits of MISR value selected by misr_mux_ctl
0xE100 CTRLMMR_MPU0_LBIST_CTRL
  fields as CTRLMMR_MCU0_LBIST_CTRL
0xE104 CTRLMMR_MPU0_LBIST_PATCOUNT
  fields as CTRLMMR_MCU0_LBIST_PATCOUNT
0xE108 CTRLMMR_MPU0_LBIST_SEED0 rw
  [31:0] PRPG_DEF — Initial seed for PRPG (bits 31:0)
0xE10C CTRLMMR_MPU0_LBIST_SEED1
  [20:0] PRPG_DEF rw — Initial seed for PRPG (bits 52:32)
0xE110 CTRLMMR_MPU0_LBIST_SPARE0 rw
  fields as CTRLMMR_MCU0_LBIST_SPARE0
0xE114 CTRLMMR_MPU0_LBIST_SPARE1 rw
  [31:0] SPARE1 — LBIST spare bits
0xE118 CTRLMMR_MPU0_LBIST_STAT (reset mask 0x7FFF7FFF)
  fields as CTRLMMR_MCU0_LBIST_STAT
0xE11C CTRLMMR_MPU0_LBIST_MISR ro reset not defined
  [31:0] MISR_RESULT — 32-bits of MISR value selected by misr_mux_ctl
0xE280 CTRLMMR_MCU0_LBIST_SIG ro reset not defined
  [31:0] MISR_SIG — MISR signature
0xE2A0 CTRLMMR_MPU0_LBIST_SIG ro reset not defined
  [31:0] MISR_SIG — MISR signature
0xE320 CTRLMMR_FUSE_CRC_STAT ro (reset mask 0xFFFFFF01)
  [n] CRC_ERR_{n} (n=1..7) — Indicates eFuse CRC error on chain {n}
0xF100 CTRLMMR_P3_CLAIM0 rw
  [31:0] PROXY1_CLAIMED — Proxy1 register claim bit
{0xF100+4i} CTRLMMR_P3_CLAIM{i} rw (i=2..5)
  [31:0] PROXY1_CLAIMED — Proxy1 register claim bit
0xF11C CTRLMMR_P3_CLAIM7 rw
  [31:0] PROXY1_CLAIMED — Proxy1 register claim bit
0x16000 CTRLMMR_CHNG_DDR4_FSP_REQ
  [8] REQ rw — Initiate FSP frequency change
  [1:0] REQ_TYPE rw — Frequency request type.
0x16004 CTRLMMR_CHNG_DDR4_FSP_ACK ro (reset mask 0xFFFFFF7E)
  [7] ACK — Frequency change acknowledge.
  [0] ERROR — Frequency change error
0x16080 CTRLMMR_DDR4_FSP_CLKCHNG_REQ ro (reset mask 0xFFFFFF7C)
  [7] REQ — DDR Controller FSP clock change request
  [1:0] REQ_TYPE — Frequency request type
0x160C0 CTRLMMR_DDR4_FSP_CLKCHNG_ACK
  [0] ACK rw — DDR FSP clock change ackowledge
0x17008 CTRLMMR_LOCK5_KICK0
  [31:1] KEY rw — Write the kick0 unlock value followed by the kick1 unlock value to unlock the write-protected Partition5 registers
  [0] UNLOCKED ro — Unlock status. When set indicates that the proper unlock sequence has been performed and the partition is unlocked for writing.
0x1700C CTRLMMR_LOCK5_KICK1 rw
  [31:0] KEY — Write the kick1 unlock value after the kick0 unlock value to unlock the write-protected Partition5 registers
0x17100 CTRLMMR_P5_CLAIM0 rw
  [31:0] PROXY1_CLAIMED — Proxy1 register claim bit
0x17104 CTRLMMR_P5_CLAIM1 rw
  [31:0] PROXY1_CLAIMED — Proxy1 register claim bit
0x1E000 CTRLMMR_PADCONFIG0 reset 0x4007
  [31] LOCK rw
  [30] WKUP_EVT ro — Wakeup event status
  [29] WKUP_EN rw — Wakeup enable
  [26] DSOUT_VAL rw — Deep Sleep output value
  [25] DSOUT_DIS rw — Deep Sleep output disable
  [24] DS_EN rw — Deep Sleep override control
  [23] ISO_BYP rw — Isolation Bypass
  [22] ISO_OVR rw — Isolation Override
  [21] TX_DIS rw — Driver Disable
  [18] RXACTIVE rw — Input enable for the Pad
  [15] FORCE_DS_EN rw — Enable pad Deep Sleep controls by overriding DMSC gating
  [14] ST_EN rw — Receiver Schmitt Trigger enable
  [13:11] DEBOUNCE_SEL rw — Selects the debouce period for the pad.
  [8] WK_LVL_POL rw — Level Sensitive Wakeup Polarity
  [7] WK_LVL_EN rw — Level Sensitive Wakeup Enable
  [5:4] VGPIO_SEL rw — Virtual MAIN_GPIO instance select. 0h - Implement GPIO in GPIO0 instance 1h - Implement GPIO in GPIO2 instance 2h - Implement GPIO in GPIO4 instance 3h - Implement GPIO in GPIO6 instance
  [3:0] MUXMODE rw — Pad functional signal mux selection 0h - Mux Mode 0 1h - Mux Mode 1 2h - Mux Mode 2 3h - Mux Mode 3 4h - Mux Mode 4 5h - Mux Mode 5 6h - Mux Mode 6 7h - Mux Mode 7 8h - Mux Mode 8 9h - Mux Mode 9 Ah - Mux Mode 10 Bh - Mux Mode 11 Ch - Mux Mode 12 Dh - Mux Mode 13 Eh - Mux Mode 14 Fh - Mux Mode 15
{0x1E000+4i} CTRLMMR_PADCONFIG{i} reset 0x8214007 (i=1..42)
  [31] LOCK rw
  [30] WKUP_EVT ro — Wakeup event status
  [29] WKUP_EN rw — Wakeup enable
  [28] DS_PULLTYPE_SEL rw — Deep Sleep pull-up/down selection
  [27] DS_PULLUD_EN rw — Deep Sleep pull-up/down enable (active low)
  [26] DSOUT_VAL rw — Deep Sleep output value
  [25] DSOUT_DIS rw — Deep Sleep output disable
  [24] DS_EN rw — Deep Sleep override control
  [23] ISO_BYP rw — Isolation Bypass
  [22] ISO_OVR rw — Isolation Override
  [21] TX_DIS rw — Driver Disable
  [20:19] DRV_STR rw — Drive Strength Control . Selects the drive strength value for LVCMOS pins. (Does not apply to other pin types)
  [18] RXACTIVE rw — Input enable for the Pad
  [17] PULLTYPESEL rw — Pad Pullup / Pulldown type selection
  [16] PULLUDEN rw — Pad Pullup / Pulldown enable. This is an active low signal.
  [15] FORCE_DS_EN rw — Enable pad Deep Sleep controls by overriding DMSC gating
  [14] ST_EN rw — Receiver Schmitt Trigger enable
  [13:11] DEBOUNCE_SEL rw — Selects the debouce period for the pad.
  [8] WK_LVL_POL rw — Level Sensitive Wakeup Polarity
  [7] WK_LVL_EN rw — Level Sensitive Wakeup Enable
  [5:4] VGPIO_SEL rw — Virtual MAIN_GPIO instance select. 0h - Implement GPIO in GPIO0 instance 1h - Implement GPIO in GPIO2 instance 2h - Implement GPIO in GPIO4 instance 3h - Implement GPIO in GPIO6 instance
  [3:0] MUXMODE rw — Pad functional signal mux selection 0h - Mux Mode 0 1h - Mux Mode 1 2h - Mux Mode 2 3h - Mux Mode 3 4h - Mux Mode 4 5h - Mux Mode 5 6h - Mux Mode 6 7h - Mux Mode 7 8h - Mux Mode 8 9h - Mux Mode 9 Ah - Mux Mode 10 Bh - Mux Mode 11 Ch - Mux Mode 12 Dh - Mux Mode 13 Eh - Mux Mode 14 Fh - Mux Mode 15
0x1E0AC CTRLMMR_PADCONFIG43 reset 0x8054007
  fields as CTRLMMR_PADCONFIG1
{0x1E000+4i} CTRLMMR_PADCONFIG{i} reset 0x8214007 (i=44..52)
  fields as CTRLMMR_PADCONFIG1
0x1E0D4 CTRLMMR_PADCONFIG53 reset 0x44007
  fields as CTRLMMR_PADCONFIG0
0x1E0D8 CTRLMMR_PADCONFIG54 reset 0x44007
  fields as CTRLMMR_PADCONFIG0
{0x1E000+4i} CTRLMMR_PADCONFIG{i} reset 0x8214007 (i=55..58)
  fields as CTRLMMR_PADCONFIG1
{0x1E000+4i} CTRLMMR_PADCONFIG{i} reset 0x8214007 (i=59..62)
  [31] LOCK rw
  [30] WKUP_EVT ro — Wakeup event status
  [29] WKUP_EN rw — Wakeup enable
  [28] DS_PULLTYPE_SEL rw — Deep Sleep pull-up/down selection
  [27] DS_PULLUD_EN rw — Deep Sleep pull-up/down enable (active low)
  [26] DSOUT_VAL rw — Deep Sleep output value
  [25] DSOUT_DIS rw — Deep Sleep output disable
  [24] DS_EN rw — Deep Sleep override control
  [23] ISO_BYP rw — Isolation Bypass
  [22] ISO_OVR rw — Isolation Override
  [21] TX_DIS rw — Driver Disable
  [18] RXACTIVE rw — Input enable for the Pad
  [17] PULLTYPESEL rw — Pad Pullup / Pulldown type selection
  [16] PULLUDEN rw — Pad Pullup / Pulldown enable. This is an active low signal.
  [15] FORCE_DS_EN rw — Enable pad Deep Sleep controls by overriding DMSC gating
  [14] ST_EN rw — Receiver Schmitt Trigger enable
  [13:11] DEBOUNCE_SEL rw — Selects the debouce period for the pad.
  [8] WK_LVL_POL rw — Level Sensitive Wakeup Polarity
  [7] WK_LVL_EN rw — Level Sensitive Wakeup Enable
  [5:4] VGPIO_SEL rw — Virtual MAIN_GPIO instance select. 0h - Implement GPIO in GPIO0 instance 1h - Implement GPIO in GPIO2 instance 2h - Implement GPIO in GPIO4 instance 3h - Implement GPIO in GPIO6 instance
  [3:0] MUXMODE rw — Pad functional signal mux selection 0h - Mux Mode 0 1h - Mux Mode 1 2h - Mux Mode 2 3h - Mux Mode 3 4h - Mux Mode 4 5h - Mux Mode 5 6h - Mux Mode 6 7h - Mux Mode 7 8h - Mux Mode 8 9h - Mux Mode 9 Ah - Mux Mode 10 Bh - Mux Mode 11 Ch - Mux Mode 12 Dh - Mux Mode 13 Eh - Mux Mode 14 Fh - Mux Mode 15
0x1E0FC CTRLMMR_PADCONFIG63 reset 0x8214000
  fields as CTRLMMR_PADCONFIG59
0x1E100 CTRLMMR_PADCONFIG64 reset 0x8214007
  fields as CTRLMMR_PADCONFIG59
0x1E104 CTRLMMR_PADCONFIG65 reset 0x8214007
  fields as CTRLMMR_PADCONFIG59
0x1E108 CTRLMMR_PADCONFIG66 reset 0x8014000
  fields as CTRLMMR_PADCONFIG1
0x1E110 CTRLMMR_PADCONFIG68 reset 0x44000
  fields as CTRLMMR_PADCONFIG1
0x1E11C CTRLMMR_PADCONFIG71 reset 0x10264000
  fields as CTRLMMR_PADCONFIG1
0x1E120 CTRLMMR_PADCONFIG72 reset 0x204007
  fields as CTRLMMR_PADCONFIG1
0x1E124 CTRLMMR_PADCONFIG73 reset 0x8214007
  fields as CTRLMMR_PADCONFIG1
0x1E164 CTRLMMR_PADCONFIG89 reset 0x8214007
  fields as CTRLMMR_PADCONFIG1
0x1E168 CTRLMMR_PADCONFIG90 reset 0x8214007
  fields as CTRLMMR_PADCONFIG1
0x1F008 CTRLMMR_LOCK7_KICK0
  [31:1] KEY rw — Write the kick0 unlock value followed by the kick1 unlock value to unlock the write-protected Partition7 registers
  [0] UNLOCKED ro — Unlock status. When set indicates that the proper unlock sequence has been performed and the partition is unlocked for writing.
0x1F00C CTRLMMR_LOCK7_KICK1 rw
  [31:0] KEY — Write the kick1 unlock value after the kick0 unlock value to unlock the write-protected Partition7 registers
{0x1F100+4i} CTRLMMR_P7_CLAIM{i} rw (i=0..2)
  [31:0] PROXY1_CLAIMED — Proxy1 register claim bit
